# STM32L412C8T6 register map
File version: 1.0
Registers are 32-bit, access not given, reset 0x0 unless marked. A register's access mark holds for its fields unless they carry their own. Offsets are from the block's base; [hi:lo] are bit positions; {n}, {i} and the like mark numbered series.

## LPUART1
Base 0x40008000
0x00 CR1
  [28] M1, [n+21] DEAT{n} (n=0..4), [n+16] DEDT{n} (n=0..4), [31:15] s, [14] CMIE, [13] MME, [12] M, [11] WAKE, [10] PCE, [9] PS, [8] PEIE, [7] TXEIE, [6] TCIE, [5] RXNEIE, [4] IDLEIE, [3] TE, [2] RE, [1] UESM, [0] UE
0x04 CR2
  [31:24] ADD, [19] MSBFIRST, [18] DATAINV, [17] TXINV, [16] RXINV, [15] SWAP, [13:12] STOP, [4] ADDM7, [23:0] s
0x08 CR3
  [23] UCESM, [22] WUFIE, [21:20] WUS, [15] DEP, [14] DEM, [13] DDRE, [12] OVRDIS, [10] CTSIE, [9] CTSE, [8] RTSE, [7] DMAT, [6] DMAR, [3] HDSEL, [31:1] s, [0] EIE
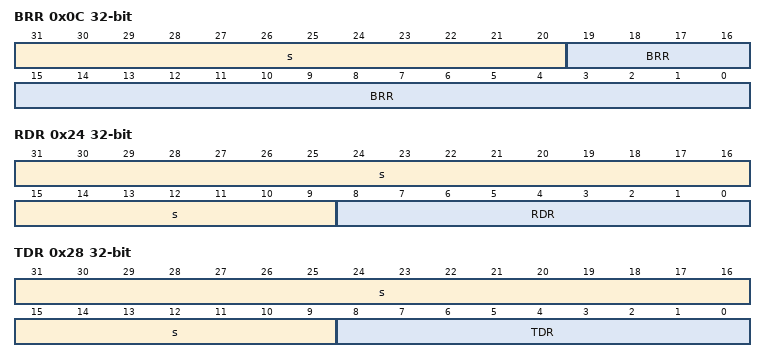
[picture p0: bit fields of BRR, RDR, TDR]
0x0C BRR
  [31:20] s, [19:0] BRR
0x18 RQR
  [3] RXFRQ, [2] MMRQ, [1] SBKRQ, [31:0] s
0x1C ISR
  [22] REACK, [21] TEACK, [20] WUF, [19] RWU, [18] SBKF, [17] CMF, [16] BUSY, [10] CTS, [9] CTSIF, [31:8] s, [7] TXE, [6] TC, [5] RXNE, [4] IDLE, [3] ORE, [2] NF, [1] FE, [0] PE
0x20 ICR
  [20] WUCF, [17] CMCF, [9] CTSCF, [6] TCCF, [31:4] s, [3] ORECF, [2] NCF, [1] FECF, [0] PECF
0x24 RDR
  [31:9] s, [8:0] RDR
0x28 TDR
  [31:9] s, [8:0] TDR

## SWPMI1
Base 0x40008800
0x00 CR
  [10] DEACT, [31:6] s, [5] SWPACT, [4] LPBK, [3] TXMODE, [2] RXMODE, [1] TXDMA, [0] RXDMA
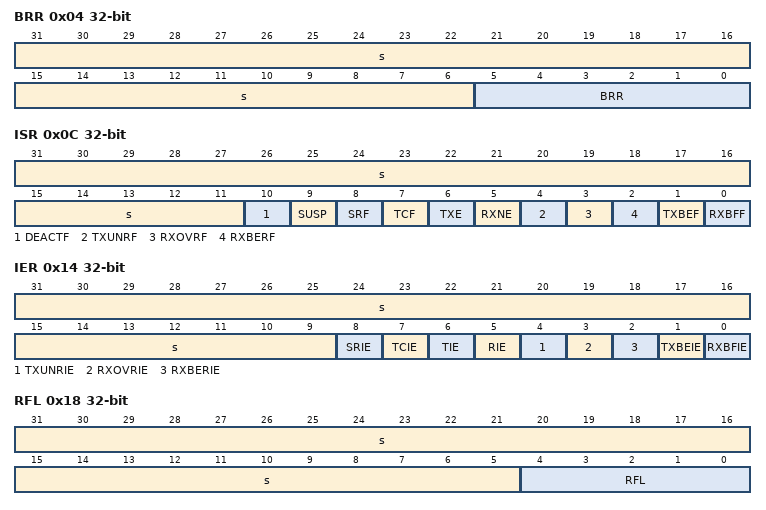
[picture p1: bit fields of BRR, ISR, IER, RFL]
0x04 BRR
  [31:6] s, [5:0] BRR
0x0C ISR
  [31:11] s, [10] DEACTF, [9] SUSP, [8] SRF, [7] TCF, [6] TXE, [5] RXNE, [4] TXUNRF, [3] RXOVRF, [2] RXBERF, [1] TXBEF, [0] RXBFF
0x10 ICR
  [8] CSRF, [7] CTCF, [31:5] s, [4] CTXUNRF, [3] CRXOVRF, [2] CRXBERF, [1] CTXBEF, [0] CRXBFF
0x14 IER
  [31:9] s, [8] SRIE, [7] TCIE, [6] TIE, [5] RIE, [4] TXUNRIE, [3] RXOVRIE, [2] RXBERIE, [1] TXBEIE, [0] RXBFIE
0x18 RFL
  [31:5] s, [4:0] RFL
0x1C TDR
  [31:0] TD
0x20 RDR
  [31:0] RD
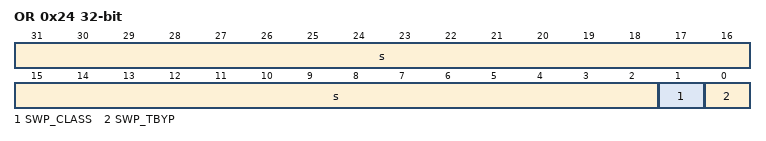
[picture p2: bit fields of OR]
0x24 OR
  [31:2] s, [1] SWP_CLASS, [0] SWP_TBYP

## SYSCFG
Base 0x40010000
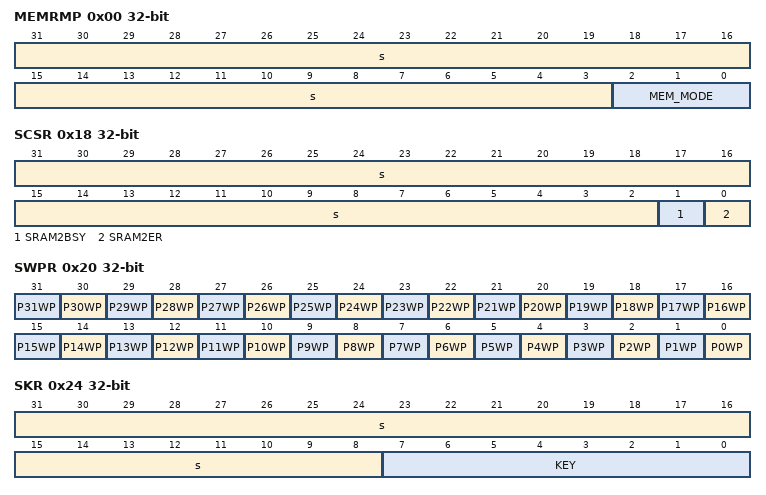
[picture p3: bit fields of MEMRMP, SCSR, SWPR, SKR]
0x00 MEMRMP
  [31:3] s, [2:0] MEM_MODE
0x04 CFGR1
  [31:26] FPU_IE, [n+19] I2C{n}_FMP (n=1..4), [n+10] I2C_PB{n}_FMP (n=6..9), [8] BOOSTEN, [25:1] s, [0] FWDIS
0x08 EXTICR1
  [4n+2:4n] EXTI{n} (n=0..3), [31:3] s
0x0C EXTICR2
  [4n-14:4n-16] EXTI{n} (n=4..7), [31:3] s
0x10 EXTICR3
  [4n-30:4n-32] EXTI{n} (n=8..11), [31:3] s
0x14 EXTICR4
  [4n-46:4n-48] EXTI{n} (n=12..15), [31:3] s
0x18 SCSR
  [31:2] s, [1] SRAM2BSY, [0] SRAM2ER
0x1C CFGR2
  [8] SPF, [31:4] s, [3] ECCL, [2] PVDL, [1] SPL, [0] CLL
0x20 SWPR
  [n] P{n}WP (n=0..31)
0x24 SKR
  [31:8] s, [7:0] KEY

## VREFBUF
Base 0x40010030
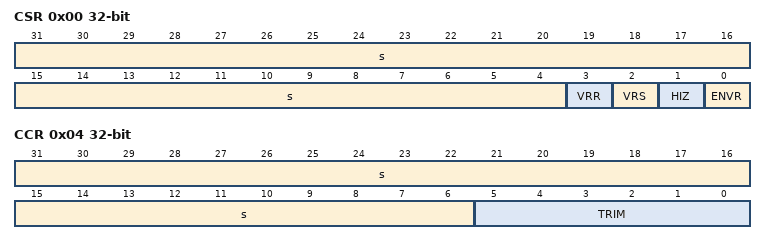
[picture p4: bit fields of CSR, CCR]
0x00 CSR
  [31:4] s, [3] VRR, [2] VRS, [1] HIZ, [0] ENVR
0x04 CCR
  [31:6] s, [5:0] TRIM

## COMP
Base 0x40010200
0x00 COMP1_CSR
  [31] LOCK, [30] VALUE, [26:25] INMESEL, [23] SCALEN, [22] BRGEN, [20:18] BLANKING, [17:16] HYST, [15] POLARITY, [8:7] INPSEL, [6:4] INMSEL, [3:2] PWRMODE, [29:1] s, [0] EN
0x04 COMP2_CSR
  [31] LOCK, [30] VALUE, [26:25] INMESEL, [23] SCALEN, [22] BRGEN, [20:18] BLANKING, [17:16] HYST, [15] POLARITY, [9] WINMODE, [8:7] INPSEL, [6:4] INMSEL, [3:2] PWRMODE, [29:1] s, [0] EN

## EXTI
Base 0x40010400
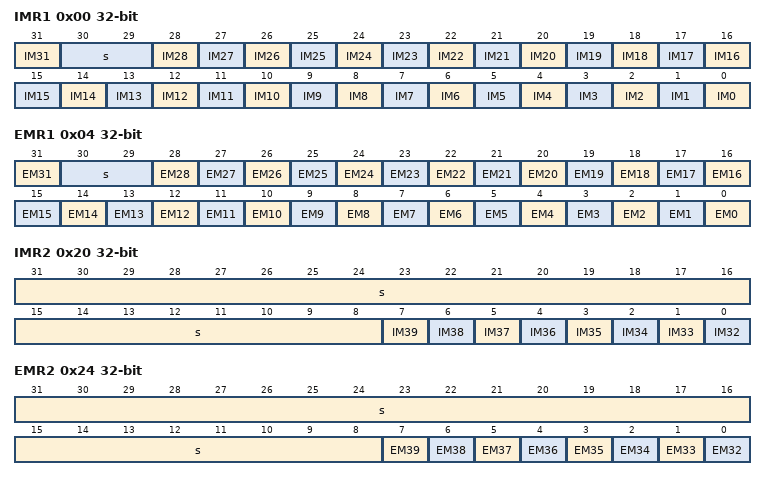
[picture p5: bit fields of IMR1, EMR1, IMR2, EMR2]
0x00 IMR1
  [31] IM31, [30:29] s, [n] IM{n} (n=0..28)
0x04 EMR1
  [31] EM31, [30:29] s, [n] EM{n} (n=0..28)
0x08 RTSR1
  [n] RT{n} (n=18..22), [31:17] s, [n] RT{n} (n=0..16)
0x0C FTSR1
  [n] FT{n} (n=18..22), [31:17] s, [n] FT{n} (n=0..16)
0x10 SWIER1
  [n] SWI{n} (n=18..22), [31:17] s, [n] SWI{n} (n=0..16)
0x14 PR1
  [n] PIF{n} (n=18..22), [31:17] s, [n] PIF{n} (n=0..16)
0x20 IMR2
  [31:8] s, [n-32] IM{n} (n=32..39)
0x24 EMR2
  [31:8] s, [n-32] EM{n} (n=32..39)
0x28 RTSR2
  [n-32] RT{n} (n=35..38), [31:0] s
0x2C FTSR2
  [n-32] FT{n} (n=35..38), [31:0] s
0x30 SWIER2
  [n-32] SWI{n} (n=35..38), [31:0] s
0x34 PR2
  [n-32] PIF{n} (n=35..38), [31:0] s

## FW
Base 0x40011C00
0x00 CSSA
  [23:8] ADD, [31:0] s
0x04 CSL
  [21:8] LENG, [31:0] s
0x08 NVDSSA
  [23:8] ADD, [31:0] s
0x0C NVDSL
  [21:8] LENG, [31:0] s
0x10 VDSSA
  [16:6] ADD, [31:0] s
0x14 VDSL
  [16:6] LENG, [31:0] s
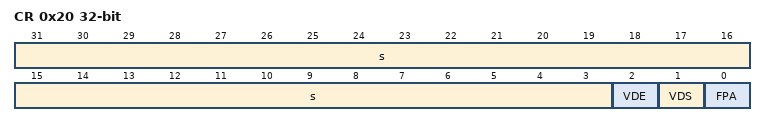
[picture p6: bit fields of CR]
0x20 CR
  [31:3] s, [2] VDE, [1] VDS, [0] FPA
